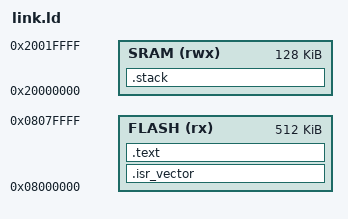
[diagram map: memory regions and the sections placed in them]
/* Minimal linker script for STM32G474 flash */
MEMORY
{
    FLASH (rx)  : ORIGIN = 0x08000000, LENGTH = 512K
    SRAM  (rwx) : ORIGIN = 0x20000000, LENGTH = 128K
}

SECTIONS
{
    .isr_vector :
    {
        . = ALIGN(4);
        KEEP(*(.isr_vector))
        . = ALIGN(4);
    } > FLASH

    .text :
    {
        . = ALIGN(4);
        *(.text*)
        *(.rodata*)
        . = ALIGN(4);
    } > FLASH

    .stack (NOLOAD) :
    {
        . = ALIGN(8);
        *(.stack)
        . = ALIGN(8);
    } > SRAM
}
